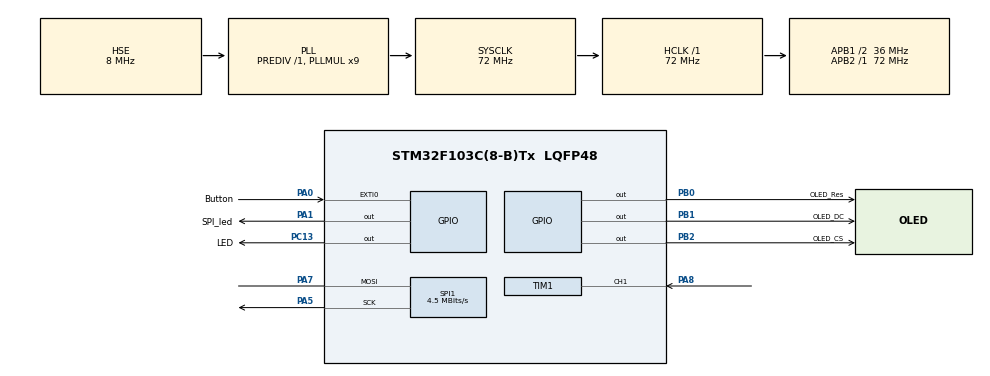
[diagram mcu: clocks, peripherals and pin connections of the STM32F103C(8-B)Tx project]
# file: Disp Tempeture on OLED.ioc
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Mcu.Family=STM32F1
Mcu.Name=STM32F103C(8-B)Tx
Mcu.Package=LQFP48
NVIC.EXTI0_IRQn=true\:2\:0\:true\:false\:true\:true\:true\:true
NVIC.PriorityGroup=NVIC_PRIORITYGROUP_4
NVIC.TIM1_UP_IRQn=true\:1\:0\:true\:false\:true\:true\:true\:true
NVIC.TIM4_IRQn=true\:3\:0\:true\:false\:true\:true\:true\:true
PA0-WKUP.GPIO_Label=Button
PA0-WKUP.GPIO_ModeDefaultEXTI=GPIO_MODE_IT_FALLING
PA0-WKUP.GPIO_PuPd=GPIO_PULLUP
PA0-WKUP.Signal=GPXTI0
PA1.GPIO_Label=SPI_led
PA1.Signal=GPIO_Output
PA13.Mode=Serial_Wire
PA13.Signal=SYS_JTMS-SWDIO
PA14.Mode=Serial_Wire
PA14.Signal=SYS_JTCK-SWCLK
PA5.Mode=Simplex_Bidirectional_Master
PA5.Signal=SPI1_SCK
PA7.Mode=Simplex_Bidirectional_Master
PA7.Signal=SPI1_MOSI
PA8.Signal=S_TIM1_CH1
PB0.GPIO_Label=OLED_Res
PB0.Signal=GPIO_Output
PB1.GPIO_Label=OLED_DC
PB1.Signal=GPIO_Output
PB2.GPIO_Label=OLED_CS
PB2.Signal=GPIO_Output
PC13-TAMPER-RTC.GPIO_Label=LED
PC13-TAMPER-RTC.GPIO_ModeDefaultOutputPP=GPIO_MODE_OUTPUT_OD
PC13-TAMPER-RTC.GPIO_PuPd=GPIO_PULLUP
PC13-TAMPER-RTC.PinState=GPIO_PIN_SET
PC13-TAMPER-RTC.Signal=GPIO_Output
PD0-OSC_IN.Mode=HSE-External-Oscillator
PD0-OSC_IN.Signal=RCC_OSC_IN
PD1-OSC_OUT.Mode=HSE-External-Oscillator
PD1-OSC_OUT.Signal=RCC_OSC_OUT
ProjectManager.HeapSize=0x200
ProjectManager.StackSize=0x400
ProjectManager.TargetToolchain=MDK-ARM V5.32
RCC.AHBFreq_Value=72000000
RCC.APB1CLKDivider=RCC_HCLK_DIV2
RCC.APB1Freq_Value=36000000
RCC.APB1TimFreq_Value=72000000
RCC.APB2Freq_Value=72000000
RCC.APB2TimFreq_Value=72000000
RCC.HCLKFreq_Value=72000000
RCC.PLLMUL=RCC_PLL_MUL9
RCC.PLLSourceVirtual=RCC_PLLSOURCE_HSE
RCC.SYSCLKFreq_VALUE=72000000
RCC.SYSCLKSource=RCC_SYSCLKSOURCE_PLLCLK
RCC.USBFreq_Value=72000000
SH.S_TIM1_CH1.0=TIM1_CH1,Input_Capture1_from_TI1
SH.S_TIM1_CH1.1=TIM1_CH1,TriggerSource_TI1FP1
SPI1.BaudRatePrescaler=SPI_BAUDRATEPRESCALER_16
SPI1.CalculateBaudRate=4.5 MBits/s
SPI1.Direction=SPI_DIRECTION_1LINE
SPI1.Mode=SPI_MODE_MASTER
SPI1.VirtualType=VM_MASTER
TIM1.Channel-Input_Capture1_from_TI1=TIM_CHANNEL_1
TIM1.Channel-Input_Capture2_from_TI1_63=TIM_CHANNEL_2
TIM1.ICPolarity_CH2=TIM_INPUTCHANNELPOLARITY_FALLING
TIM1.Period=65536-1
TIM1.Prescaler=3-1
TIM4.Period=500-1
TIM4.Prescaler=7200-1
VP_TIM1_VS_ClockSourceINT.Mode=Internal
VP_TIM1_VS_ControllerModeReset.Mode=Reset Mode
VP_TIM1_VS_indirect_ch1.Mode=Input_Capture2_from_TI1_63
VP_TIM4_VS_ClockSourceINT.Mode=Internal
board=custom

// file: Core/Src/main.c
/* USER CODE BEGIN Header */
/**
  ******************************************************************************
  * @file           : main.c
  * @brief          : Main program body
  ******************************************************************************
  * @attention
  *
  * Copyright (c) 2024 STMicroelectronics.
  * All rights reserved.
  *
  * This software is licensed under terms that can be found in the LICENSE file
  * in the root directory of this software component.
  * If no LICENSE file comes with this software, it is provided AS-IS.
  *
  ******************************************************************************
  */
/* USER CODE END Header */
#include "main.h"
#include "spi.h"
#include "tim.h"
#include "gpio.h"

/* USER CODE BEGIN Includes */
#include "ssd1306.h"
#include "ssd1306_tests.h"
#include "ssd1306_fonts.h"
#include <string.h>
#include <stdio.h>
/* USER CODE END Includes */

/* USER CODE BEGIN PTD */
float freq,dt,temp,tempslow;
/* USER CODE END PTD */

void SystemClock_Config(void);
/* USER CODE BEGIN PFP */
void Draw_temp(void);
/* USER CODE END PFP */

int main(void)
{

  /* MCU Configuration--------------------------------------------------------*/

  /* Reset of all peripherals, Initializes the Flash interface and the Systick. */
  HAL_Init();

  /* Configure the system clock */
  SystemClock_Config();

  /* Initialize all configured peripherals */
  MX_GPIO_Init();
  MX_TIM1_Init();
  MX_SPI1_Init();
  MX_TIM4_Init();
  /* USER CODE BEGIN 2 */

	HAL_TIM_Base_Start_IT(&htim1);
	HAL_TIM_IC_Start(&htim1,TIM_CHANNEL_1);
	HAL_TIM_IC_Start(&htim1,TIM_CHANNEL_2);
	HAL_TIM_Base_Start_IT(&htim4);
	ssd1306_Init();
  /* USER CODE END 2 */

  /* Infinite loop */
  while (1)
  {

  }
}

void SystemClock_Config(void)
{
  RCC_OscInitTypeDef RCC_OscInitStruct = {0};
  RCC_ClkInitTypeDef RCC_ClkInitStruct = {0};

  /** Initializes the RCC Oscillators according to the specified parameters
  * in the RCC_OscInitTypeDef structure.
  */
  RCC_OscInitStruct.OscillatorType = RCC_OSCILLATORTYPE_HSE;
  RCC_OscInitStruct.HSEState = RCC_HSE_ON;
  RCC_OscInitStruct.HSEPredivValue = RCC_HSE_PREDIV_DIV1;
  RCC_OscInitStruct.HSIState = RCC_HSI_ON;
  RCC_OscInitStruct.PLL.PLLState = RCC_PLL_ON;
  RCC_OscInitStruct.PLL.PLLSource = RCC_PLLSOURCE_HSE;
  RCC_OscInitStruct.PLL.PLLMUL = RCC_PLL_MUL9;
  if (HAL_RCC_OscConfig(&RCC_OscInitStruct) != HAL_OK)
  {
    Error_Handler();
  }

  /** Initializes the CPU, AHB and APB buses clocks
  */
  RCC_ClkInitStruct.ClockType = RCC_CLOCKTYPE_HCLK|RCC_CLOCKTYPE_SYSCLK
                              |RCC_CLOCKTYPE_PCLK1|RCC_CLOCKTYPE_PCLK2;
  RCC_ClkInitStruct.SYSCLKSource = RCC_SYSCLKSOURCE_PLLCLK;
  RCC_ClkInitStruct.AHBCLKDivider = RCC_SYSCLK_DIV1;
  RCC_ClkInitStruct.APB1CLKDivider = RCC_HCLK_DIV2;
  RCC_ClkInitStruct.APB2CLKDivider = RCC_HCLK_DIV1;

  if (HAL_RCC_ClockConfig(&RCC_ClkInitStruct, FLASH_LATENCY_2) != HAL_OK)
  {
    Error_Handler();
  }
}

void Error_Handler(void)
{
  __disable_irq();
  while (1)
  {
  }
}
